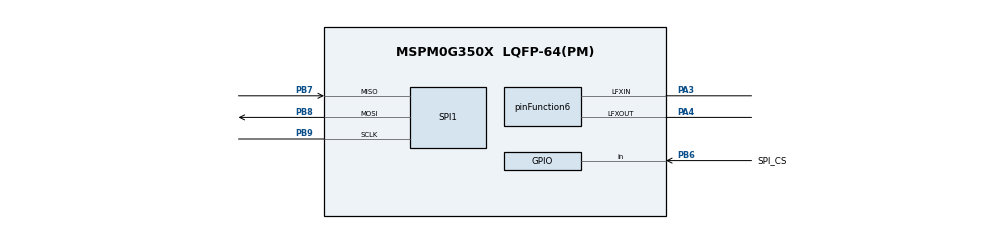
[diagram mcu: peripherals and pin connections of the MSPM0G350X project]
/**
 * @cliArgs --device "MSPM0G350X" --package "LQFP-64(PM)" --part "Default" --product "mspm0_sdk@0.52.00.03"
 * @versions {"tool":"1.15.0+2729"}
 */

/**
 * Import the modules used in this configuration.
 */
const Board  = scripting.addModule("/ti/driverlib/Board");
const GPIO   = scripting.addModule("/ti/driverlib/GPIO", {}, false);
const GPIO1  = GPIO.addInstance();
const RTC    = scripting.addModule("/ti/driverlib/RTC");
const SPI    = scripting.addModule("/ti/driverlib/SPI", {}, false);
const SPI1   = SPI.addInstance();
const SYSCTL = scripting.addModule("/ti/driverlib/SYSCTL");

/**
 * Write custom configuration values to the imported modules.
 */
const gate7  = system.clockTree["MFCLKGATE"];
gate7.enable = true;

const mux3       = system.clockTree["EXCLKMUX"];
mux3.inputSelect = "EXCLKMUX_LFCLK";

const mux5       = system.clockTree["EXLFMUX"];
mux5.inputSelect = "EXLFMUX_XTAL";

const mux9       = system.clockTree["LFXTMUX"];
mux9.inputSelect = "LFXTMUX_TRUE";

const pinFunction6                        = system.clockTree["LFXT"];
pinFunction6.inputFreq                    = 32.18;
pinFunction6.enable                       = true;
pinFunction6.LFCLKDriveStrength           = "HIGHER";
pinFunction6.peripheral.lfxInPin.$assign  = "PA3";
pinFunction6.peripheral.lfxOutPin.$assign = "PA4";

const monitor             = scripting.addModule("/ti/clockTree/monitor.js", {}, false);
const monitor1            = monitor.addInstance({}, false);
monitor1.$name            = "ti_clockTree_monitor0";
pinFunction6.LFCLKMonitor = monitor1;


GPIO1.$name                               = "GPIO_GRP_0";
GPIO1.associatedPins.create(2);
GPIO1.associatedPins[0].$name             = "PIN_0";
GPIO1.associatedPins[0].launchPadShortcut = "LED1En";
GPIO1.associatedPins[1].$name             = "SPI_CS";
GPIO1.associatedPins[1].direction         = "INPUT";
GPIO1.associatedPins[1].ioStructure       = "SD";
GPIO1.associatedPins[1].assignedPort      = "PORTB";
GPIO1.associatedPins[1].assignedPin       = "6";
GPIO1.associatedPins[1].interruptEn       = true;
GPIO1.associatedPins[1].polarity          = "RISE_FALL";
GPIO1.associatedPins[1].pin.$assign       = "PB6";


SPI1.$name                      = "SPI_target";
SPI1.rxFifoThreshold            = "DL_SPI_RX_FIFO_LEVEL_ONE_FRAME";
SPI1.mode                       = "PERIPHERAL";
SPI1.txFifoThreshold            = "DL_SPI_TX_FIFO_LEVEL_3_4_EMPTY";
SPI1.rxTimeoutValue             = 1;
SPI1.enabledInterrupts          = ["IDLE","RX"];
SPI1.frameFormat                = "MOTO3";
SPI1.peripheral.$assign         = "SPI1";
SPI1.peripheral.sclkPin.$assign = "PB9";
SPI1.peripheral.mosiPin.$assign = "PB8";
SPI1.peripheral.misoPin.$assign = "PB7";

SYSCTL.clockTreeEn = true;

/**
 * Pinmux solution for unlocked pins/peripherals. This ensures that minor changes to the automatic solver in a future
 * version of the tool will not impact the pinmux you originally saw.  These lines can be completely deleted in order to
 * re-solve from scratch.
 */
pinFunction6.peripheral.$suggestSolution     = "SYSCTL";
Board.peripheral.$suggestSolution            = "DEBUGSS";
Board.peripheral.swclkPin.$suggestSolution   = "PA20";
Board.peripheral.swdioPin.$suggestSolution   = "PA19";
GPIO1.associatedPins[0].pin.$suggestSolution = "PA0";
RTC.peripheral.$suggestSolution              = "RTC";
